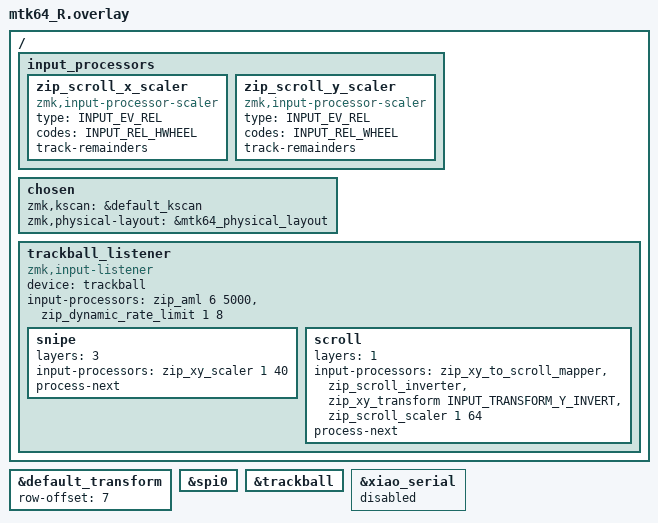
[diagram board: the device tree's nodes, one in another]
#include "mtk64.dtsi"
#include "mtk64_trackball.dtsi"


/ {
    input_processors {
        zip_scroll_x_scaler: zip_scroll_x_scaler {
            compatible = "zmk,input-processor-scaler";
            #input-processor-cells = <2>;
            type = <INPUT_EV_REL>;
            codes = <INPUT_REL_HWHEEL>;
            track-remainders;
        };
    };
};


 / {
    input_processors {
        zip_scroll_y_scaler: zip_scroll_y_scaler {
            compatible = "zmk,input-processor-scaler";
            #input-processor-cells = <2>;
            type = <INPUT_EV_REL>;
            codes = <INPUT_REL_WHEEL>;
            track-remainders;
        };
    };
};




/ {
    chosen {
        zmk,kscan = &default_kscan;
        zmk,physical-layout = &mtk64_physical_layout;
    };
};

&default_transform {
    row-offset = <7>;
};

/*
&kscan0 {
    gpios
        = <&xiao_d 1 GPIO_ACTIVE_HIGH> 
        , <&xiao_d 2 GPIO_ACTIVE_HIGH> 
        , <&xiao_d 3 GPIO_ACTIVE_HIGH> 
        , <&xiao_d 6 GPIO_ACTIVE_HIGH>
        , <&xiao_d 7 GPIO_ACTIVE_HIGH> 
        , <&xiao_d 8 GPIO_ACTIVE_HIGH> 
        , <&xiao_d 9 GPIO_ACTIVE_HIGH> 	
    ;
};
*/

/ {
    trackball_listener: trackball_listener {
        compatible = "zmk,input-listener";
        status = "okay";
        device = <&trackball>;
        input-processors = <&zip_aml 6 5000>, <&zip_dynamic_rate_limit 1 8>;

        snipe {
            layers = <3>;
            input-processors = <&zip_xy_scaler 1 40>;
            process-next;
        };

        scroll {
            layers = <1>;
            input-processors = 
                <&zip_xy_to_scroll_mapper>, 
                <&zip_scroll_inverter>, 
                <&zip_xy_transform INPUT_TRANSFORM_Y_INVERT>, 
//<&zip_scroll_x_scaler 0 1>,
                <&zip_scroll_scaler 1 64>;
            process-next;
        };
    };
};

&spi0 {
    status = "okay";
};

&trackball { 
    status = "okay";
};

&xiao_serial { status = "disabled"; };
